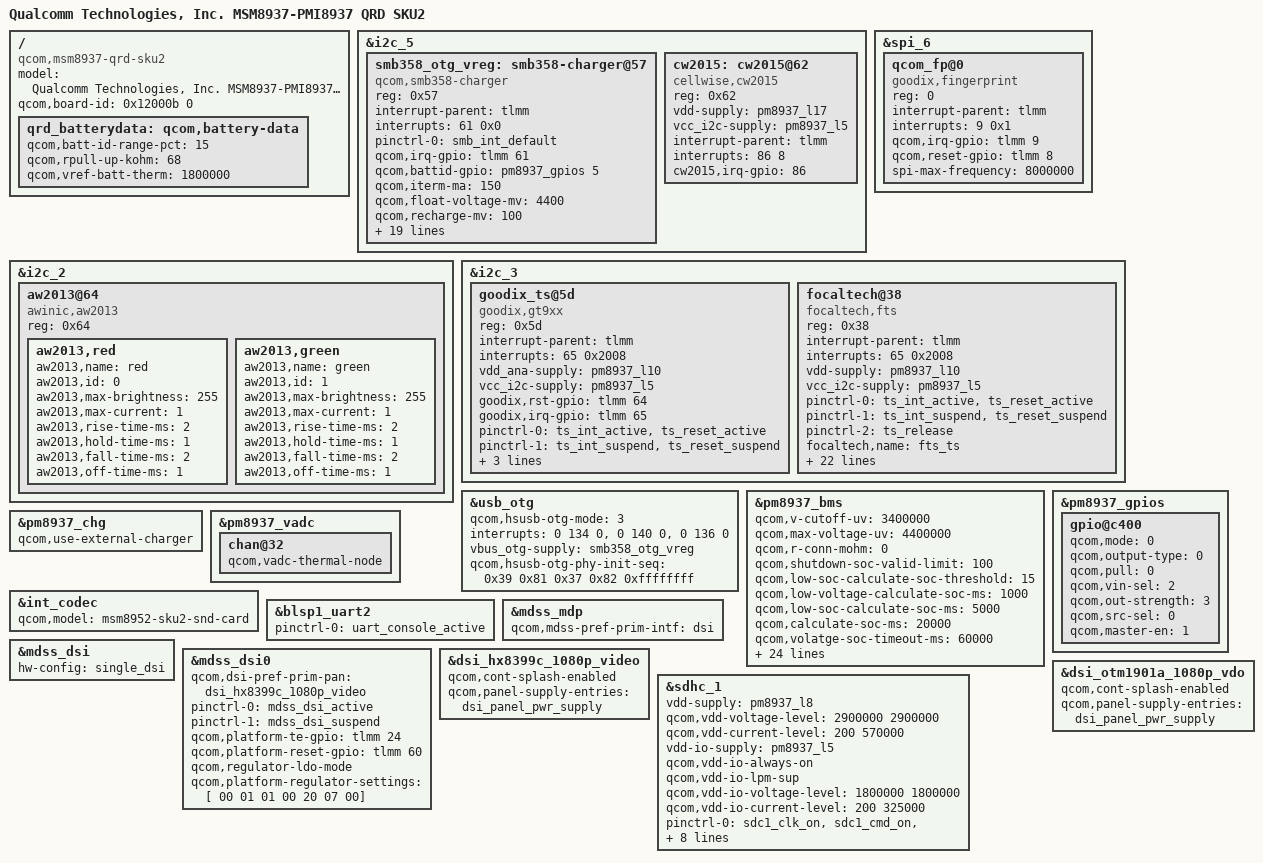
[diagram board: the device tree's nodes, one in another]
/*
 * Copyright (c) 2015-2016, The Linux Foundation. All rights reserved.
 *
 * This program is free software; you can redistribute it and/or modify
 * it under the terms of the GNU General Public License version 2 and
 * only version 2 as published by the Free Software Foundation.
 *
 * This program is distributed in the hope that it will be useful,
 * but WITHOUT ANY WARRANTY; without even the implied warranty of
 * MERCHANTABILITY or FITNESS FOR A PARTICULAR PURPOSE.  See the
 * GNU General Public License for more details.
 */

/dts-v1/;

#include "msm8937.dtsi"
#include "msm8937-qrd.dtsi"
#include "msm8937-mdss-panels.dtsi"

/ {
	model = "Qualcomm Technologies, Inc. MSM8937-PMI8937 QRD SKU2";
	compatible = "qcom,msm8937-qrd-sku2","qcom,msm8937-qrd", "qcom,msm8937", "qcom,qrd";
	qcom,board-id= <0x12000b 0>;
};
//+Other_platform_modify 20160520 xuji.wt add C3 charging config
&i2c_5 {
	status = "ok";
	smb358_otg_vreg: smb358-charger@57 {
    compatible = "qcom,smb358-charger";
    reg = <0x57>;
    interrupt-parent = <&tlmm>;
    interrupts = <61 0x0>;
    pinctrl-names = "default";
    pinctrl-0 = <&smb_int_default>;   
    qcom,irq-gpio = <&tlmm 61 0x0>;   
    qcom,battid-gpio = <&pm8937_gpios 5 0>;
    qcom,iterm-ma = <150>;	//set Termination Current to 150mA by yangpingao.wt 20160824
    qcom,float-voltage-mv = <4400>;	//set float voltage to 4400mV by yangpingao.wt 20160805
    qcom,recharge-mv = <100>;	//set recharge voltage to 4280mV by yangpingao.wt 20160711
    regulator-name = "smb358_otg_vreg";
    qcom,thermal-mitigation = <1500 1000 700 500>;	//set thermal-mitigation to 1500mA by yangpingao.wt 20160711
    qcom,fastchg-current-max-ma = <1500>;	//set fastchg current to 1500mA by yangpingao.wt 20160711
    qcom,bms-psy-name = "bms";
    //qcom,iterm-disabled;
    qcom,bms-controlled-charging;
    //qcom,chg-inhibit-disabled;
    qcom,chg-vadc = <&pm8937_vadc>;
    qcom,chg-adc_tm = <&pm8937_adc_tm>;    
    qcom,using-pmic-therm;
    qcom,bat-present-decidegc = <(300)>;    //Unit: 0.1 degree centigride    
    qcom,disable-apsd;  //platfor_modify 20151026 huangfusheng.wt use pm8916 charger detect
/*
 * Below properties are used for enable JEITA 
 */    
    qcom,hot-bat-decidegc = <600>;
    qcom,warm-bat-decidegc = <500>;	//set charge warm mode 50 ~ 60 by yangpingao.wt 20160711
    qcom,cool-bat-decidegc = <100>;
    qcom,cold-bat-decidegc = <0>;
    qcom,warm-bat-ma = <1500>;	//set charge warm mode fastchg current to 1500mA by yangpingao.wt 20160711
    qcom,cool-bat-ma = <1000>;   //Bug_15544 20160312 huangfusheng.wt modify cool-bat-ma low temp charging current
    qcom,warm-bat-mv = <4100>;
    qcom,cool-bat-mv = <4380>;	//set charge cool mode max charge voltage to 4380mV by yangpingao.wt 20160711
    qcom,battery-fcc = <4000>;   // +Other_platform modify 20151202 huangfusheng.wt add battery capacity discription
    status = "ok";
   };  
    cw2015: cw2015@62 {
    compatible = "cellwise,cw2015";
    reg = <0x62>;
    vdd-supply = <&pm8937_l17>;
    vcc_i2c-supply = <&pm8937_l5>;
		interrupt-parent = <&tlmm>;
	  interrupts = <86 8>;
	  cw2015,irq-gpio=<86>;
   };
};

//goodix fingerprint 
&spi_6 { /* BLSP1 QUP3 */
               status = "ok";
               qcom_fp@0 {
                       status = "ok";
                       compatible = "goodix,fingerprint";
                       reg = <0>;
                       interrupt-parent = <&tlmm>;
                       interrupts = <9 0x1>;
                       qcom,irq-gpio = <&tlmm 9 0x00>;
                       qcom,reset-gpio = <&tlmm 8 0x00>;
                       //gf,power-gpio = <&tlmm 20 0x00>;
                       spi-max-frequency = <8000000>;
               };
       };
/* add */
&i2c_2 {
	aw2013@64 {/* add for breath led. */
		compatible = "awinic,aw2013";
		reg = <0x64>;
		//vdd-supply = <&pm8937_l17>;
		//vcc-supply = <&pm8937_l6>;

		aw2013,red {
			aw2013,name = "red";
			aw2013,id = <0>;
			aw2013,max-brightness = <255>;
			aw2013,max-current = <1>;
			aw2013,rise-time-ms = <2>;
			aw2013,hold-time-ms = <1>;
			aw2013,fall-time-ms = <2>;
			aw2013,off-time-ms = <1>;
		};

		aw2013,green {
			aw2013,name = "green";
			aw2013,id = <1>;
			aw2013,max-brightness = <255>;
			aw2013,max-current = <1>;
			aw2013,rise-time-ms = <2>;
			aw2013,hold-time-ms = <1>;
			aw2013,fall-time-ms = <2>;
			aw2013,off-time-ms = <1>;
		};
	};
};

&i2c_3 { /* BLSP1 QUP3 */
		status = "ok";

		goodix_ts@5d {
			compatible = "goodix,gt9xx";
			reg = <0x5d>;
			interrupt-parent = <&tlmm>;
			interrupts = <65 0x2008>;
			vdd_ana-supply = <&pm8937_l10>;
			vcc_i2c-supply = <&pm8937_l5>;
			goodix,rst-gpio = <&tlmm 64 0x00>;
			goodix,irq-gpio = <&tlmm 65 0x2008>;
			pinctrl-names = "pmx_ts_active","pmx_ts_suspend","pmx_ts_release";
			pinctrl-0 = <&ts_int_active &ts_reset_active>;
			pinctrl-1 = <&ts_int_suspend &ts_reset_suspend>;
			pinctrl-2 = <&ts_release>;

			goodix,cfg-group1 = [
				 4E 38 04 80 07 0A 35 01 01 18
				 28 08 50 32 03 05 00 00 00 00
				 00 00 06 18 1A 1E 14 8C 2E 0E
				 47 49 F4 0A F4 0A 00 DB 33 1D
				 00 00 00 00 00 00 00 32 00 00
				 23 1E 64 94 80 0F 00 00 00 04
				 78 22 00 65 2B 00 58 37 00 4E
				 46 00 48 59 00 48 18 38 60 00
				 F0 4A 3A FF FF 27 00 00 00 00
				 00 00 00 00 FF FF 00 00 00 00
				 00 00 00 00 00 19 46 00 00 00
				 00 32 06 04 02 1C 1A 18 16 14
				 12 08 0A 0C 0E 10 00 00 00 00
				 00 00 00 00 00 00 00 00 00 00
				 00 00 0F 10 12 13 14 0C 0A 08
				 06 04 02 00 16 2A 29 28 26 24
				 22 21 20 1F 1E 1D 1C 18 00 00
				 00 00 00 00 00 00 00 00 00 00
				 00 00 00 00 C7 01];
		};

		focaltech@38{
			compatible = "focaltech,fts";
			reg = <0x38>;
			interrupt-parent = <&tlmm>;
			interrupts = <65 0x2008>;
			vdd-supply = <&pm8937_l10>;
			vcc_i2c-supply = <&pm8937_l5>;
			/* pins used by touchscreen */
			pinctrl-names = "pmx_ts_active","pmx_ts_suspend",
				"pmx_ts_release";
			pinctrl-0 = <&ts_int_active &ts_reset_active>;
			pinctrl-1 = <&ts_int_suspend &ts_reset_suspend>;
			pinctrl-2 = <&ts_release>;
			focaltech,name = "fts_ts";
			focaltech,family-id = <0x54>;
			focaltech,reset-gpio = <&tlmm 64 0x00>;
			focaltech,irq-gpio = <&tlmm 65 0x2008>;
			focaltech,display-coords = <0 0 1080 1920>;
			focaltech,panel-coords = <0 0 1080 1920>;
			/*ftech,button-map= <139 102 158>;*/
			focaltech,virtual-key1 = <139 560 2000>;/*menu*/
			focaltech,virtual-key2 = <102 360 2000>;/*home*/
			focaltech,virtual-key3 = <158 160 2000>;/*back*/
			focaltech,no-force-update;
			focaltech,i2c-pull-up;
			focaltech,group-id = <1>;
			focaltech,hard-reset-delay-ms = <20>;
			focaltech,soft-reset-delay-ms = <200>;
			focaltech,num-max-touches = <10>;
			focaltech,fw-delay-aa-ms = <30>;
			focaltech,fw-delay-55-ms = <30>;
			focaltech,fw-upgrade-id1 = <0x79>;
			focaltech,fw-upgrade-id2 = <0x18>;
			focaltech,fw-delay-readid-ms = <10>;
			focaltech,fw-delay-era-flsh-ms = <2000>;
			focaltech,fw-auto-cal;
			focaltech,ignore-id-check;
		};
};
/* end */

/ {
	qrd_batterydata: qcom,battery-data {
		qcom,batt-id-range-pct = <15>;	
		qcom,rpull-up-kohm = <68>;          //BAT_ID pin PullUp resistor
		qcom,vref-batt-therm = <1800000>;    //BAT_ID pin PullUp Voltage
		#include "batterydata-qrd-sku2-4v35-2590mah.dtsi"
		#include "batterydata-wingtech-desai_SAMSUNG-4v4-4000mah.dtsi"
		#include "batterydata-wingtech-feimaotui_SONY-4v4-4000mah.dtsi"
		#include "batterydata-wingtech-xingwangda_ATL-4v4-4000mah.dtsi"
		#include "batterydata-wingtech-guangyu_Coslight-4v4-4000mah.dtsi"
	};
};

&usb_otg {	

        qcom,hsusb-otg-mode = <3>;
        interrupts = <0 134 0>,<0 140 0>,<0 136 0>;
        interrupt-names = "core_irq", "async_irq", "phy_irq";
        vbus_otg-supply = <&smb358_otg_vreg>;
	qcom,hsusb-otg-phy-init-seq =
		<0x39 0x81 0x37 0x82 0xffffffff>;
};

&pm8937_bms {    
       //+Other_project_modify 20150914 huangfusheng.wt add dts config separate from msm-pm8916.dtsi 
            qcom,v-cutoff-uv = <3400000>;
	    qcom,max-voltage-uv = <4400000>;
	    qcom,r-conn-mohm = <0>;
	    qcom,shutdown-soc-valid-limit = <100>;
            qcom,low-soc-calculate-soc-threshold = <15>;
	    qcom,low-voltage-calculate-soc-ms = <1000>;
	    qcom,low-soc-calculate-soc-ms = <5000>;
	    qcom,calculate-soc-ms = <20000>;
            qcom,volatge-soc-timeout-ms = <60000>;
	    qcom,low-voltage-threshold = <3450000>;
	    qcom,s3-ocv-tolerence-uv = <1200>;
	    qcom,s2-fifo-length = <5>;
	    qcom,low-soc-fifo-length = <2>;
            qcom,resume-soc = <99>;
       	//+Other_platform_modify 20150927 huangfusheng.wt add dts config for current terminate

        qcom,warm-bat-temperature = <450>;
        qcom,cool-bat-temperature = <100>;
        qcom,warm-chg-full-term-current = <(-150000)> ;
        qcom,cool-chg-full-term-current = <(-150000)> ;
        qcom,normal-chg-full-term-current = <(-180000)>;

        qcom,warm-chg-full-term_vbat = <4000000>;
        qcom,cool-chg-full-term_vbat = <4250000>;
        qcom,normal-chg-full-term_vbat = <4350000>;

        qcom,warm-chg-full-term-ocv = <4000000> ;
        qcom,cool-chg-full-term-ocv = <4200000> ;
        qcom,normal-chg-full-term-ocv = <4330000>;

        qcom,cool-chg-full-term-soc = <85>;
				qcom,cool-chg-recharge-soc = <84>;
				qcom,warm-chg-full-term-soc = <70>;
				qcom,warm-chg-recharge-soc = <68>;
        qcom,current-report-eoc;
            qcom,use-reported-soc;
	    qcom,report-charger-eoc;
            status = "ok";
           //-Other_project_modify 20150914 huangfusheng.wt add dts config separate from msm-pm8916.dtsi 
};

&pm8937_bms {
	status = "ok";
	qcom,battery-data = <&qrd_batterydata>;
};

/*&usb_otg {
       qcom,hsusb-otg-mode = <3>;
       qcom,usbid-gpio = <&tlmm 110 0>;
       pinctrl-names = "default";
       pinctrl-0 = <&usbid_default>;
       vbus_otg-supply = <&smb358_otg_vreg>;
};*/

&pm8937_gpios {
	gpio@c400 {
		qcom,mode = <0>;
		qcom,output-type = <0>;
		qcom,pull = <0>;
		qcom,vin-sel = <2>;
		qcom,out-strength = <3>;
		qcom,src-sel = <0>;
		qcom,master-en = <1>;
		status = "okay";
	};
};

&pm8937_chg {
	status = "ok";
	qcom,use-external-charger;
};
//-Other_platform_modify 20160520 xuji.wt add C3 charging config
&pm8937_vadc {
chan@32 {	
	qcom,vadc-thermal-node;
	};
};

&int_codec {
	qcom,model = "msm8952-sku2-snd-card";
};

&blsp1_uart2 {
	status = "ok";
	pinctrl-names = "default";
	pinctrl-0 = <&uart_console_active>;
};
&mdss_mdp {
	qcom,mdss-pref-prim-intf = "dsi";
};

&mdss_dsi {
	hw-config = "single_dsi";
};

&mdss_dsi0 {
	qcom,dsi-pref-prim-pan = <&dsi_hx8399c_1080p_video>;
	//qcom,dsi-pref-sub-pan = <&dsi_otm1901a_1080p_vdo>;
	pinctrl-names = "mdss_default", "mdss_sleep";
	pinctrl-0 = <&mdss_dsi_active>;
	pinctrl-1 = <&mdss_dsi_suspend>;
	qcom,platform-te-gpio = <&tlmm 24 0>;
	qcom,platform-reset-gpio = <&tlmm 60 0>;
	//vsp-supply = <&tps65132_pos>;
	//vsn-supply = <&tps65132_neg>;
    //panelvddio-supply = <&pm8937_l6>;
    
    
	qcom,regulator-ldo-mode;
	qcom,platform-regulator-settings = [ 00 01 01 00 20 07 00];
};

&dsi_hx8399c_1080p_video {
	qcom,cont-splash-enabled;
	qcom,panel-supply-entries = <&dsi_panel_pwr_supply>;
};

&dsi_otm1901a_1080p_vdo {
	qcom,cont-splash-enabled;
	qcom,panel-supply-entries = <&dsi_panel_pwr_supply>;
};

// -Other_platform modify 20160511 xuji.wt add charging debug
&sdhc_1 {
	/* device core power supply */
	vdd-supply = <&pm8937_l8>;
	qcom,vdd-voltage-level = <2900000 2900000>;
	qcom,vdd-current-level = <200 570000>;

	/* device communication power supply */
	vdd-io-supply = <&pm8937_l5>;
	qcom,vdd-io-always-on;
	qcom,vdd-io-lpm-sup;
	qcom,vdd-io-voltage-level = <1800000 1800000>;
	qcom,vdd-io-current-level = <200 325000>;

	pinctrl-names = "active", "sleep";
	pinctrl-0 = <&sdc1_clk_on &sdc1_cmd_on &sdc1_data_on &sdc1_rclk_on>;
	pinctrl-1 = <&sdc1_clk_off &sdc1_cmd_off &sdc1_data_off &sdc1_rclk_off>;

	qcom,clk-rates = <400000 20000000 25000000 50000000 100000000 192000000
								384000000>;
	qcom,nonremovable;
	qcom,bus-speed-mode = "HS400_1p8v", "HS200_1p8v", "DDR_1p8v";

	status = "ok";
};
